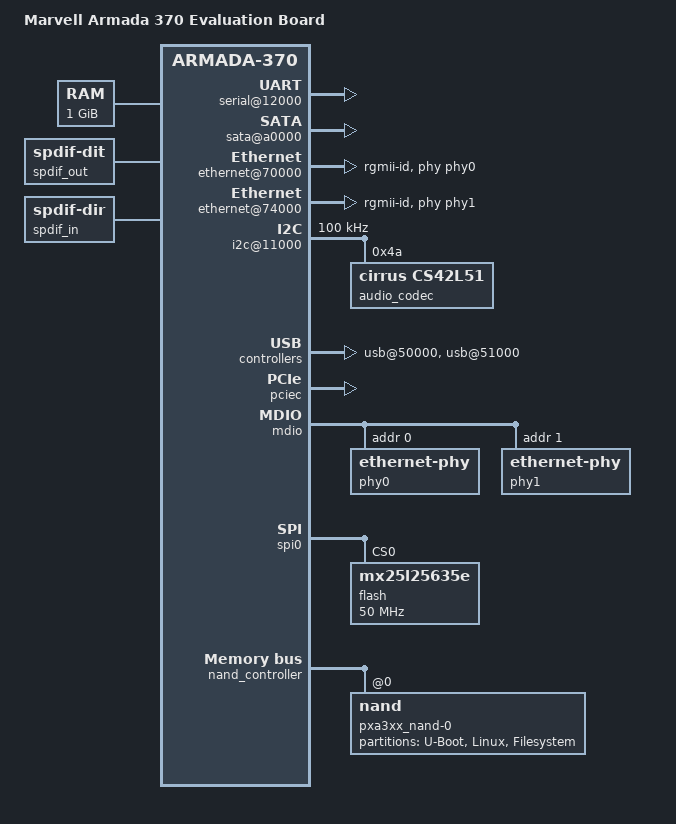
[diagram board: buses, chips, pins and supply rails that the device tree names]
/dts-v1/;
#include "armada-370.dtsi"
/ {
	model = "Marvell Armada 370 Evaluation Board";
	compatible = "marvell,a370-db", "marvell,armada370", "marvell,armada-370-xp";
	chosen {
		stdout-path = "serial0:115200n8";
	};
	memory@0 {
		device_type = "memory";
		reg = <0x00000000 0x40000000>;  
	};
	soc {
		ranges = <MBUS_ID(0xf0, 0x01) 0 0xf1000000 0x100000
			  MBUS_ID(0x01, 0xe0) 0 0xfff00000 0x100000
			  MBUS_ID(0x09, 0x01) 0 0xf1100000 0x10000>;
		internal-regs {
			serial@12000 {
				status = "okay";
			};
			sata@a0000 {
				nr-ports = <2>;
				status = "okay";
			};
			ethernet@70000 {
				pinctrl-0 = <&ge0_rgmii_pins>;
				pinctrl-names = "default";
				status = "okay";
				phy = <&phy0>;
				phy-mode = "rgmii-id";
			};
			ethernet@74000 {
				pinctrl-0 = <&ge1_rgmii_pins>;
				pinctrl-names = "default";
				status = "okay";
				phy = <&phy1>;
				phy-mode = "rgmii-id";
			};
			i2c@11000 {
				pinctrl-0 = <&i2c0_pins>;
				pinctrl-names = "default";
				clock-frequency = <100000>;
				status = "okay";
				audio_codec: audio-codec@4a {
					#sound-dai-cells = <0>;
					compatible = "cirrus,cs42l51";
					reg = <0x4a>;
				};
			};
			audio-controller@30000 {
				pinctrl-0 = <&i2s_pins2>;
				pinctrl-names = "default";
				status = "okay";
			};
			mvsdio@d4000 {
				pinctrl-0 = <&sdio_pins1>;
				pinctrl-names = "default";
				status = "disabled";
				broken-cd;
			};
			usb@50000 {
				status = "okay";
			};
			usb@51000 {
				status = "okay";
			};
		};
	};
	sound {
		compatible = "simple-audio-card";
		simple-audio-card,name = "Armada 370 DB Audio";
		simple-audio-card,mclk-fs = <256>;
		simple-audio-card,widgets =
			"Headphone", "Out Jack",
			"Line", "In Jack";
		simple-audio-card,routing =
			"Out Jack", "HPL",
			"Out Jack", "HPR",
			"AIN1L", "In Jack",
			"AIN1L", "In Jack";
		status = "okay";
		simple-audio-card,dai-link@0 {
			format = "i2s";
			cpu {
				sound-dai = <&audio_controller 0>;
			};
			codec {
				sound-dai = <&audio_codec>;
			};
		};
		simple-audio-card,dai-link@1 {
			format = "i2s";
			cpu {
				sound-dai = <&audio_controller 1>;
			};
			codec {
				sound-dai = <&spdif_out>;
			};
		};
		simple-audio-card,dai-link@2 {
			format = "i2s";
			cpu {
				sound-dai = <&audio_controller 1>;
			};
			codec {
				sound-dai = <&spdif_in>;
			};
		};
	};
	spdif_out: spdif-out {
		#sound-dai-cells = <0>;
		compatible = "linux,spdif-dit";
	};
	spdif_in: spdif-in {
		#sound-dai-cells = <0>;
		compatible = "linux,spdif-dir";
	};
};
&pciec {
	status = "okay";
	pcie@1,0 {
		status = "okay";
	};
	pcie@2,0 {
		status = "okay";
	};
};
&mdio {
	pinctrl-0 = <&mdio_pins>;
	pinctrl-names = "default";
	phy0: ethernet-phy@0 {
		reg = <0>;
	};
	phy1: ethernet-phy@1 {
		reg = <1>;
	};
};
&spi0 {
	pinctrl-0 = <&spi0_pins2>;
	pinctrl-names = "default";
	status = "okay";
	flash@0 {
		#address-cells = <1>;
		#size-cells = <1>;
		compatible = "mx25l25635e", "jedec,spi-nor";
		reg = <0>;  
		spi-max-frequency = <50000000>;
	};
};
&nand_controller {
	status = "okay";
	nand@0 {
		reg = <0>;
		label = "pxa3xx_nand-0";
		nand-rb = <0>;
		marvell,nand-keep-config;
		nand-on-flash-bbt;
		partitions {
			compatible = "fixed-partitions";
			#address-cells = <1>;
			#size-cells = <1>;
			partition@0 {
				label = "U-Boot";
				reg = <0 0x800000>;
			};
			partition@800000 {
				label = "Linux";
				reg = <0x800000 0x800000>;
			};
			partition@1000000 {
				label = "Filesystem";
				reg = <0x1000000 0x3f000000>;
			};
		};
	};
};
